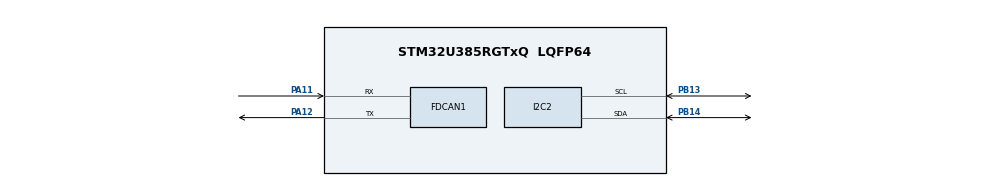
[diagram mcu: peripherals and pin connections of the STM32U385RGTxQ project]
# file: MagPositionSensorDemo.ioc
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CORTEX_M33_NS.userName=CORTEX_M33
FDCAN1.AutoRetransmission=ENABLE
FDCAN1.CalculateBaudRateNominal=99173
FDCAN1.CalculateTimeBitNominal=10083
FDCAN1.CalculateTimeQuantumNominal=83.33333333333333
FDCAN1.DataSyncJumpWidth=3
FDCAN1.DataTimeSeg1=8
FDCAN1.DataTimeSeg2=3
FDCAN1.NominalPrescaler=1
FDCAN1.NominalSyncJumpWidth=30
FDCAN1.NominalTimeSeg1=90
FDCAN1.NominalTimeSeg2=30
FDCAN1.StdFiltersNbr=1
FDCAN1.TransmitPause=ENABLE
I2C2.Timing=0x40000A0B
Mcu.Family=STM32U3
Mcu.Name=STM32U385RGTxQ
Mcu.Package=LQFP64
NVIC.PriorityGroup=NVIC_PRIORITYGROUP_4
PA11.Mode=FDCAN_Activate
PA11.Signal=FDCAN1_RX
PA12.Mode=FDCAN_Activate
PA12.Signal=FDCAN1_TX
PB13.Mode=I2C
PB13.Signal=I2C2_SCL
PB14.Mode=I2C
PB14.Signal=I2C2_SDA
ProjectManager.HeapSize=0x200
ProjectManager.StackSize=0x400
ProjectManager.TargetToolchain=STM32CubeIDE
RCC.ADCFreq_Value=12000000
RCC.AHBFreq_Value=12000000
RCC.APB1Freq_Value=12000000
RCC.APB1TimFreq_Value=12000000
RCC.APB2Freq_Value=12000000
RCC.APB2TimFreq_Value=12000000
RCC.APB3Freq_Value=12000000
RCC.CortexFreq_Value=1500000
RCC.HCLKFreq_Value=12000000
RCC.HSE_VALUE=16000000
RCC.HSI48_VALUE=48000000
RCC.HSI_VALUE=16000000
RCC.LSE_VALUE=32768
RCC.LSIDIV_VALUE=32000
RCC.SYSCLKFreq_VALUE=12000000
RCC.USBFreq_Value=12000000
VP_ICACHE_VS_ICACHE.Mode=DefaultMode
VP_MEMORYMAP_VS_MEMORYMAP.Mode=CurAppReg
VP_PWR_VS_DBSignals.Mode=DisableDeadBatterySignals
VP_PWR_VS_LPOM.Mode=PowerOptimisation
VP_PWR_VS_SECSignals.Mode=Security/Privilege
board=custom

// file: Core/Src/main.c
/* USER CODE BEGIN Header */
/**
  ******************************************************************************
  * @file           : main.c
  * @brief          : Main program body
  ******************************************************************************
  * @attention
  *
  * Copyright (c) 2026 STMicroelectronics.
  * All rights reserved.
  *
  * This software is licensed under terms that can be found in the LICENSE file
  * in the root directory of this software component.
  * If no LICENSE file comes with this software, it is provided AS-IS.
  *
   ******************************************************************************
  */
/* USER CODE END Header */
#include "main.h"

/* USER CODE BEGIN Includes */
#include "app.h"
/* USER CODE END Includes */

FDCAN_HandleTypeDef hfdcan1;

I2C_HandleTypeDef hi2c2;

void SystemClock_Config(void);
static void MX_GPIO_Init(void);
static void MX_I2C2_Init(void);
static void MX_FDCAN1_Init(void);
static void MX_ICACHE_Init(void);

int main(void)
{

  /* MCU Configuration--------------------------------------------------------*/

  /* Reset of all peripherals, Initializes the Flash interface and the Systick. */
  HAL_Init();

  /* Configure the system clock */
  SystemClock_Config();

  /* Initialize all configured peripherals */
  MX_GPIO_Init();
  MX_I2C2_Init();
  MX_FDCAN1_Init();
  MX_ICACHE_Init();
  /* USER CODE BEGIN 2 */
  if (App_Init(&hi2c2, &hfdcan1) != HAL_OK)
  {
    Error_Handler();
  }

  /* USER CODE END 2 */

  /* Infinite loop */
  /* USER CODE BEGIN WHILE */

  while (1)
  {
    App_Run();
  }
    /* USER CODE END WHILE */

}

void SystemClock_Config(void)
{
  RCC_OscInitTypeDef RCC_OscInitStruct = {0};
  RCC_ClkInitTypeDef RCC_ClkInitStruct = {0};

  /** Configure the System Power Supply
  */
  if (HAL_PWREx_ConfigSupply(PWR_SMPS_SUPPLY) != HAL_OK)
  {
    Error_Handler();
  }

  /** Configure the main internal regulator output voltage
  */
  if (HAL_PWREx_ControlVoltageScaling(PWR_REGULATOR_VOLTAGE_SCALE2) != HAL_OK)
  {
    Error_Handler();
  }

  /** Initializes the CPU, AHB and APB buses clocks
  */
  RCC_OscInitStruct.OscillatorType = RCC_OSCILLATORTYPE_MSIS;
  RCC_OscInitStruct.MSISState = RCC_MSI_ON;
  RCC_OscInitStruct.MSISSource = RCC_MSI_RC0;
  RCC_OscInitStruct.MSISDiv = RCC_MSI_DIV8;
  if (HAL_RCC_OscConfig(&RCC_OscInitStruct) != HAL_OK)
  {
    Error_Handler();
  }

  /** Initializes the CPU, AHB and APB buses clocks
  */
  RCC_ClkInitStruct.ClockType = RCC_CLOCKTYPE_HCLK|RCC_CLOCKTYPE_SYSCLK
                              |RCC_CLOCKTYPE_PCLK1|RCC_CLOCKTYPE_PCLK2
                              |RCC_CLOCKTYPE_PCLK3;
  RCC_ClkInitStruct.SYSCLKSource = RCC_SYSCLKSOURCE_MSIS;
  RCC_ClkInitStruct.AHBCLKDivider = RCC_SYSCLK_DIV1;
  RCC_ClkInitStruct.APB1CLKDivider = RCC_HCLK_DIV1;
  RCC_ClkInitStruct.APB2CLKDivider = RCC_HCLK_DIV1;
  RCC_ClkInitStruct.APB3CLKDivider = RCC_HCLK_DIV1;

  if (HAL_RCC_ClockConfig(&RCC_ClkInitStruct, FLASH_LATENCY_0) != HAL_OK)
  {
    Error_Handler();
  }
}

static void MX_FDCAN1_Init(void)
{

  hfdcan1.Instance = FDCAN1;
  hfdcan1.Init.ClockDivider = FDCAN_CLOCK_DIV1;
  hfdcan1.Init.FrameFormat = FDCAN_FRAME_CLASSIC;
  hfdcan1.Init.Mode = FDCAN_MODE_NORMAL;
  hfdcan1.Init.AutoRetransmission = ENABLE;
  hfdcan1.Init.TransmitPause = ENABLE;
  hfdcan1.Init.ProtocolException = DISABLE;
  hfdcan1.Init.NominalPrescaler = 1;
  hfdcan1.Init.NominalSyncJumpWidth = 30;
  hfdcan1.Init.NominalTimeSeg1 = 90;
  hfdcan1.Init.NominalTimeSeg2 = 30;
  hfdcan1.Init.DataPrescaler = 1;
  hfdcan1.Init.DataSyncJumpWidth = 3;
  hfdcan1.Init.DataTimeSeg1 = 8;
  hfdcan1.Init.DataTimeSeg2 = 3;
  hfdcan1.Init.StdFiltersNbr = 1;
  hfdcan1.Init.ExtFiltersNbr = 0;
  hfdcan1.Init.TxFifoQueueMode = FDCAN_TX_FIFO_OPERATION;
  if (HAL_FDCAN_Init(&hfdcan1) != HAL_OK)
  {
    Error_Handler();
  }

}

static void MX_I2C2_Init(void)
{

  hi2c2.Instance = I2C2;
  hi2c2.Init.Timing = 0x40000A0B;
  hi2c2.Init.OwnAddress1 = 0;
  hi2c2.Init.AddressingMode = I2C_ADDRESSINGMODE_7BIT;
  hi2c2.Init.DualAddressMode = I2C_DUALADDRESS_DISABLE;
  hi2c2.Init.OwnAddress2 = 0;
  hi2c2.Init.OwnAddress2Masks = I2C_OA2_NOMASK;
  hi2c2.Init.GeneralCallMode = I2C_GENERALCALL_DISABLE;
  hi2c2.Init.NoStretchMode = I2C_NOSTRETCH_DISABLE;
  if (HAL_I2C_Init(&hi2c2) != HAL_OK)
  {
    Error_Handler();
  }

  /** Configure Analogue filter
  */
  if (HAL_I2CEx_ConfigAnalogFilter(&hi2c2, I2C_ANALOGFILTER_ENABLE) != HAL_OK)
  {
    Error_Handler();
  }

  /** Configure Digital filter
  */
  if (HAL_I2CEx_ConfigDigitalFilter(&hi2c2, 0) != HAL_OK)
  {
    Error_Handler();
  }

}

static void MX_ICACHE_Init(void)
{

  /** Enable instruction cache (default 2-ways set associative cache)
  */
  if (HAL_ICACHE_Enable() != HAL_OK)
  {
    Error_Handler();
  }

}

static void MX_GPIO_Init(void)
{

  /* GPIO Ports Clock Enable */
  __HAL_RCC_GPIOB_CLK_ENABLE();
  __HAL_RCC_GPIOA_CLK_ENABLE();

}

void Error_Handler(void)
{
  __disable_irq();
  while(1){}
}
